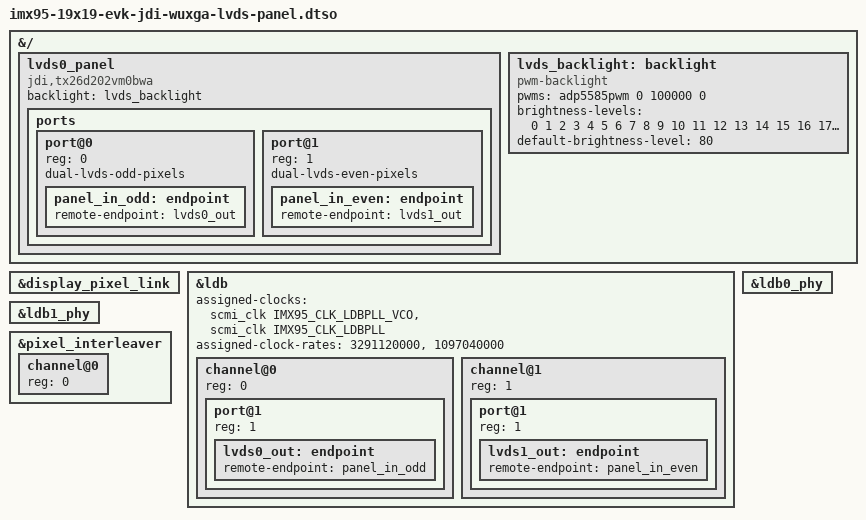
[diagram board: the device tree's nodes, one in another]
// SPDX-License-Identifier: (GPL-2.0+ OR MIT)
/*
 * Copyright 2023 NXP
 */
/dts-v1/;
/plugin/;

#include <dt-bindings/clock/fsl,imx95-clock.h>

&{/} {
	lvds0_panel {
		compatible = "jdi,tx26d202vm0bwa";
		backlight = <&lvds_backlight>;

		ports {
			#address-cells = <1>;
			#size-cells = <0>;

			port@0 {
				reg = <0>;
				dual-lvds-odd-pixels;
				panel_in_odd: endpoint {
					remote-endpoint = <&lvds0_out>;
				};
			};


			port@1 {
				reg = <1>;
				dual-lvds-even-pixels;
				panel_in_even: endpoint {
					remote-endpoint = <&lvds1_out>;
				};
			};
		};
	};

	lvds_backlight: backlight {
		compatible = "pwm-backlight";
		pwms = <&adp5585pwm 0 100000 0>;
		brightness-levels = < 0  1  2  3  4  5  6  7  8  9
				     10 11 12 13 14 15 16 17 18 19
				     20 21 22 23 24 25 26 27 28 29
				     30 31 32 33 34 35 36 37 38 39
				     40 41 42 43 44 45 46 47 48 49
				     50 51 52 53 54 55 56 57 58 59
				     60 61 62 63 64 65 66 67 68 69
				     70 71 72 73 74 75 76 77 78 79
				     80 81 82 83 84 85 86 87 88 89
				     90 91 92 93 94 95 96 97 98 99
				    100>;
		default-brightness-level = <80>;
	};
};

&display_pixel_link {
	status = "okay";
};

&ldb {
	#address-cells = <1>;
	#size-cells = <0>;
	assigned-clocks = <&scmi_clk IMX95_CLK_LDBPLL_VCO>,
			  <&scmi_clk IMX95_CLK_LDBPLL>;
	assigned-clock-rates = <3291120000>, <1097040000>;
	status = "okay";

	channel@0 {
		#address-cells = <1>;
		#size-cells = <0>;
		reg = <0>;
		status = "okay";

		port@1 {
			reg = <1>;

			lvds0_out: endpoint {
				remote-endpoint = <&panel_in_odd>;
			};
		};
	};

	channel@1 {
		#address-cells = <1>;
		#size-cells = <0>;
		reg = <1>;
		status = "okay";

		port@1 {
			reg = <1>;

			lvds1_out: endpoint {
				remote-endpoint = <&panel_in_even>;
			};
		};
	};
};

&ldb0_phy {
	status = "okay";
};

&ldb1_phy {
	status = "okay";
};

&pixel_interleaver {
	#address-cells = <1>;
	#size-cells = <0>;
	status = "okay";

	channel@0 {
		reg = <0>;
		status = "okay";
	};
};
